VERSION ""

NS_ :

BS_:

BU_: XXX r  1 + 8

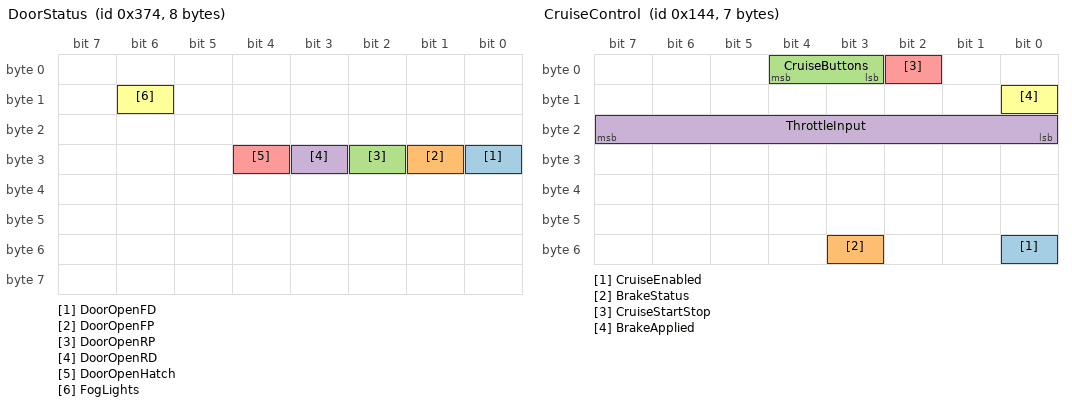
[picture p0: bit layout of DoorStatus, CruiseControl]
BO_ 884 DoorStatus: 8 XXX
 SG_ DoorOpenFD : 24|1@0+ (1,0) [0|1] "" XXX
 SG_ DoorOpenFP : 25|1@0+ (1,0) [0|1] "" XXX
 SG_ DoorOpenRP : 26|1@0+ (1,0) [0|1] "" XXX
 SG_ DoorOpenRD : 27|1@0+ (1,0) [0|1] "" XXX
 SG_ DoorOpenHatch : 28|1@0+ (1,0) [0|1] "" XXX
 SG_ FogLights : 14|1@1+ (1,0) [0|3] "on/off" XXX

BO_ 324 CruiseControl: 7 XXX
 SG_ CruiseEnabled : 48|1@0+ (1,0) [0|0] "" XXX
 SG_ BrakeStatus : 51|1@0+ (1,0) [0|0] "" XXX
 SG_ CruiseButtons : 4|2@0+ (1,0) [0|3] "" XXX
 SG_ ThrottleInput : 16|8@1+ (1,0) [0|255] "" XXX
 SG_ CruiseStartStop : 2|1@1+ (1,0) [0|1] "" XXX
 SG_ BrakeApplied : 8|1@0+ (1,0) [0|0] "" XXX

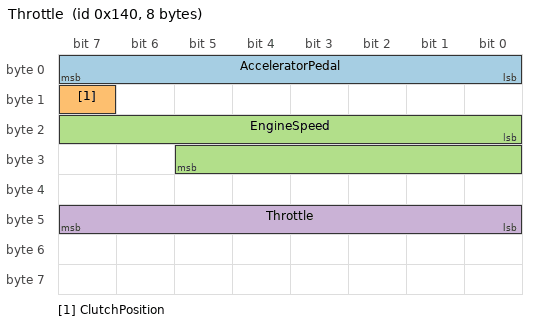
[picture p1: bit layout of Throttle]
BO_ 320 Throttle: 8 XXX
 SG_ AcceleratorPedal : 0|8@1+ (0.392157,0) [0|100] "percent" r
 SG_ ClutchPosition : 15|1@1+ (1,1) [0|-5] "on/off" ,
 SG_ EngineSpeed : 16|14@1+ (1,0) [|] "rpm" ,
 SG_ Throttle : 40|8@1+ (0.392157,0) [0|100] "percent" XXX

BO_ 209 Brakes: 8 XXX
 SG_ BrakePosition : 16|8@1+ (1,0) [0|255] "%" XXX

BO_ 2 Steering: 8 XXX
 SG_ SteeringAngle : 7|16@0- (0.1,0) [-500|500] "degree" XXX

BO_ 642 NEW_MSG_2: 8 XXX

BO_ 338 Lights: 8 XXX
 SG_ HighBeam : 61|1@1+ (1,0) [0|1] "on/off" XXX
 SG_ Lights : 58|2@1+ (1,0) [|] "" XXX

BO_ 322 NEW_MSG_3: 8 XXX

BO_ 208 Steering: 8 XXX
 SG_ SteeringAngle : 0|16@1- (.1,0) [NaN|0] "degrees" 1

BO_ 864 Temperature: 8 XXX
 SG_ OilTemperature : 16|8@1+ (0,-40) [|] "degrees" +
 SG_ CoolantTemperature : 16|8@1+ (0,0) [|] "degrees" 8

BO_ 321 Transmission: 8 XXX
 SG_ GearIndicator : 0|0@0+ (8,0) [4|0] "1" ,

BO_ 880 NEW_MSG_1: 8 XXX

CM_ SG_ 338 Lights "00 = off, 01 = running lights, 11 = lights on";
VAL_ 324 CruiseEnabled 1 "On" 0 "Off" ;
VAL_ 324 BrakeStatus 1 "On" 0 "Off" ;
VAL_ 324 CruiseButtons 2 "Set" 1 "Resume" ;
VAL_ 324 BrakeApplied 1 "On" 0 "Off" ;
CM_ "CHFFR_METRIC 2 STEER_ANGLE STEER_ANGLE 0.36 180"""";
